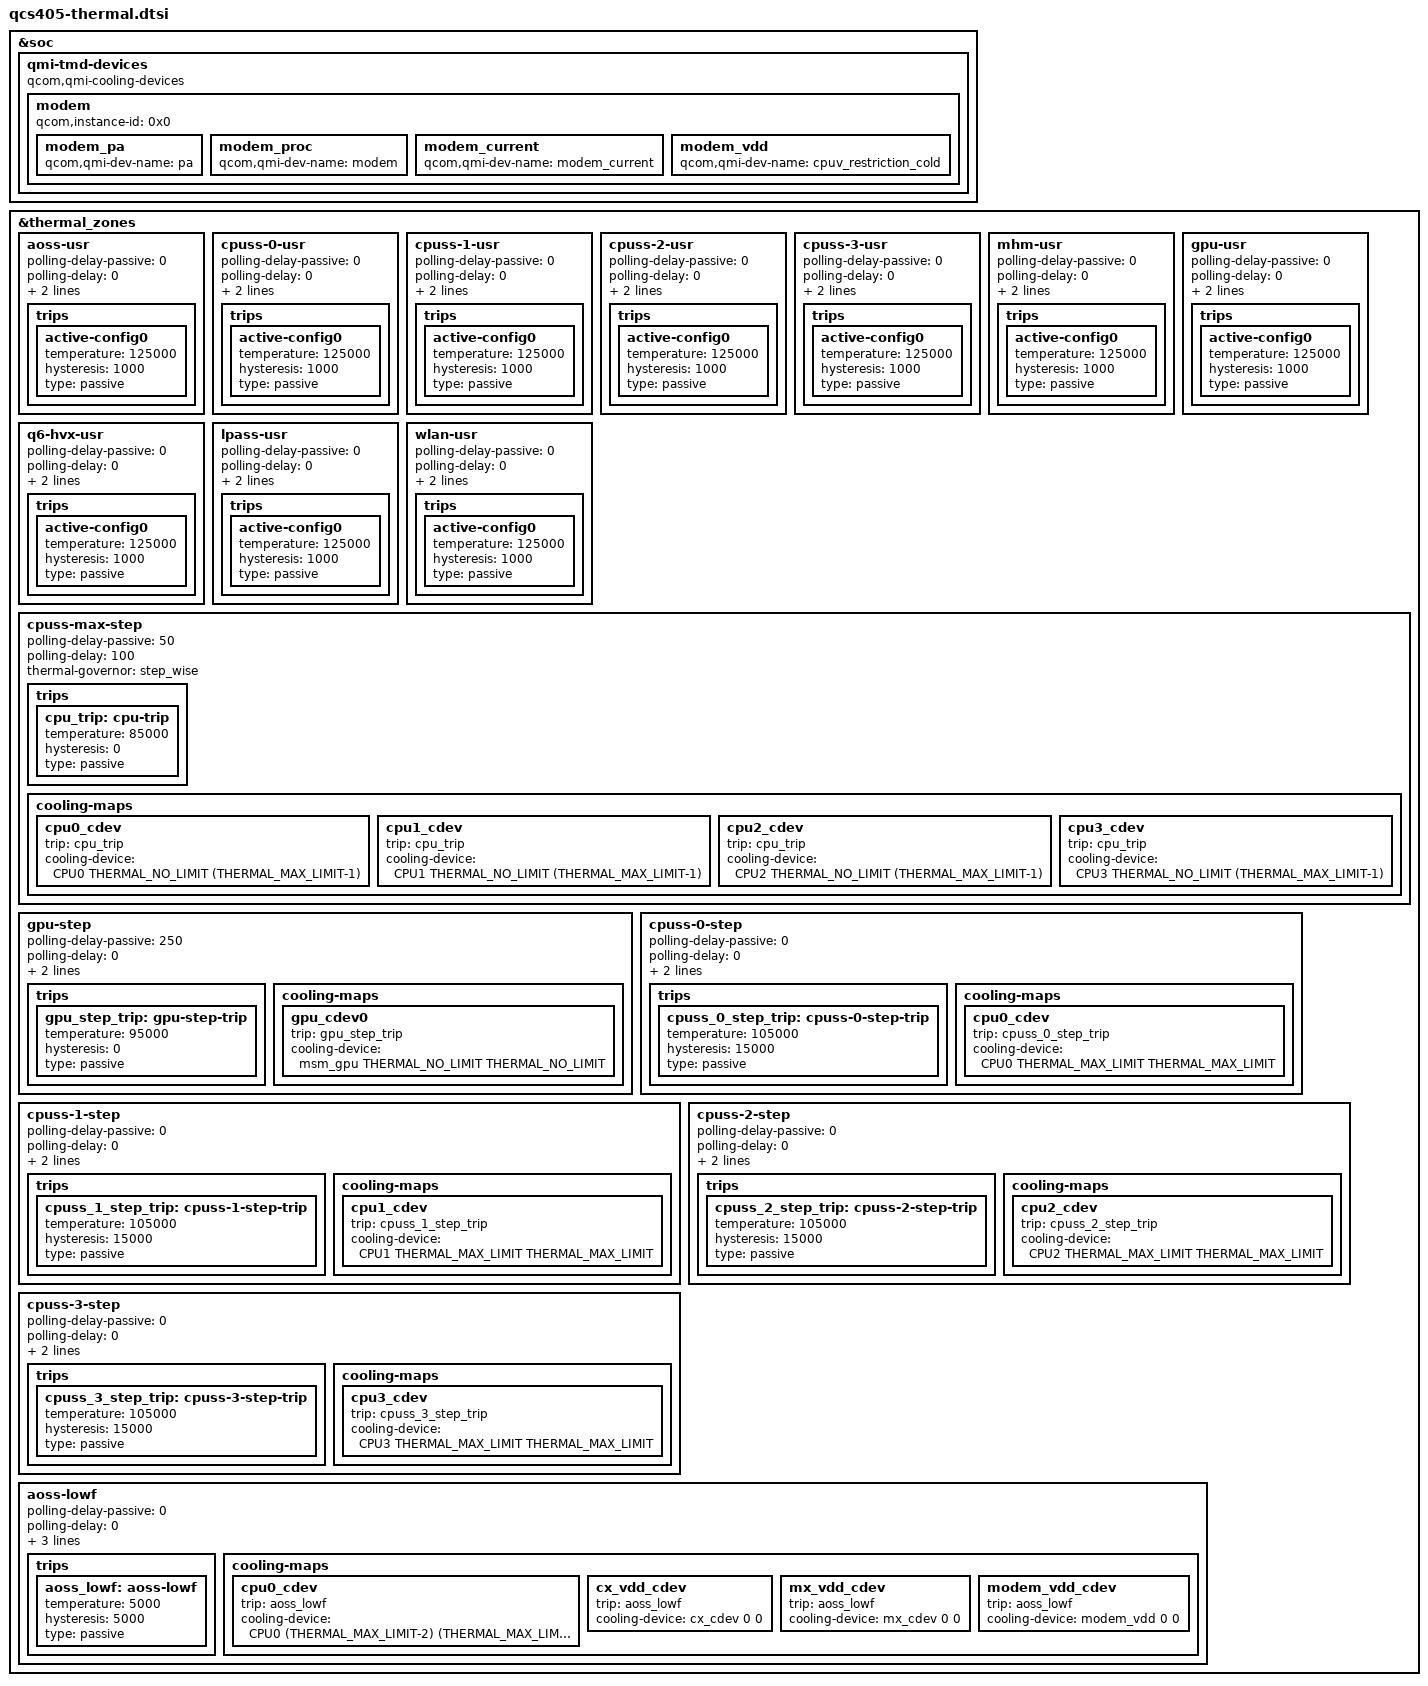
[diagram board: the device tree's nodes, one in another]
/* Copyright (c) 2018, The Linux Foundation. All rights reserved.
 *
 * This program is free software; you can redistribute it and/or modify
 * it under the terms of the GNU General Public License version 2 and
 * only version 2 as published by the Free Software Foundation.
 *
 * This program is distributed in the hope that it will be useful,
 * but WITHOUT ANY WARRANTY; without even the implied warranty of
 * MERCHANTABILITY or FITNESS FOR A PARTICULAR PURPOSE.  See the
 * GNU General Public License for more details.
 */

#include <dt-bindings/thermal/thermal.h>

&soc {
	qmi-tmd-devices {
		compatible = "qcom,qmi-cooling-devices";

		modem {
			qcom,instance-id = <0x0>;

			modem_pa: modem_pa {
				qcom,qmi-dev-name = "pa";
				#cooling-cells = <2>;
			};

			modem_proc: modem_proc {
				qcom,qmi-dev-name = "modem";
				#cooling-cells = <2>;
			};

			modem_current: modem_current {
				qcom,qmi-dev-name = "modem_current";
				#cooling-cells = <2>;
			};

			modem_vdd: modem_vdd {
				qcom,qmi-dev-name = "cpuv_restriction_cold";
				#cooling-cells = <2>;
			};
		};
	};
};

&thermal_zones {
	aoss-usr {
		polling-delay-passive = <0>;
		polling-delay = <0>;
		thermal-governor = "user_space";
		thermal-sensors = <&tsens0 0>;
		trips {
			active-config0 {
				temperature = <125000>;
				hysteresis = <1000>;
				type = "passive";
			};
		};
	};

	cpuss-0-usr {
		polling-delay-passive = <0>;
		polling-delay = <0>;
		thermal-governor = "user_space";
		thermal-sensors = <&tsens0 1>;
		trips {
			active-config0 {
				temperature = <125000>;
				hysteresis = <1000>;
				type = "passive";
			};
		};
	};

	cpuss-1-usr {
		polling-delay-passive = <0>;
		polling-delay = <0>;
		thermal-governor = "user_space";
		thermal-sensors = <&tsens0 2>;
		trips {
			active-config0 {
				temperature = <125000>;
				hysteresis = <1000>;
				type = "passive";
			};
		};
	};

	cpuss-2-usr {
		polling-delay-passive = <0>;
		polling-delay = <0>;
		thermal-governor = "user_space";
		thermal-sensors = <&tsens0 3>;
		trips {
			active-config0 {
				temperature = <125000>;
				hysteresis = <1000>;
				type = "passive";
			};
		};
	};

	cpuss-3-usr {
		polling-delay-passive = <0>;
		polling-delay = <0>;
		thermal-sensors = <&tsens0 4>;
		thermal-governor = "user_space";
		trips {
			active-config0 {
				temperature = <125000>;
				hysteresis = <1000>;
				type = "passive";
			};
		};
	};

	mhm-usr {
		polling-delay-passive = <0>;
		polling-delay = <0>;
		thermal-sensors = <&tsens0 5>;
		thermal-governor = "user_space";
		trips {
			active-config0 {
				temperature = <125000>;
				hysteresis = <1000>;
				type = "passive";
			};
		};
	};

	gpu-usr {
		polling-delay-passive = <0>;
		polling-delay = <0>;
		thermal-sensors = <&tsens0 6>;
		thermal-governor = "user_space";
		trips {
			active-config0 {
				temperature = <125000>;
				hysteresis = <1000>;
				type = "passive";
			};
		};
	};

	q6-hvx-usr {
		polling-delay-passive = <0>;
		polling-delay = <0>;
		thermal-sensors = <&tsens0 7>;
		thermal-governor = "user_space";
		trips {
			active-config0 {
				temperature = <125000>;
				hysteresis = <1000>;
				type = "passive";
			};
		};
	};

	lpass-usr {
		polling-delay-passive = <0>;
		polling-delay = <0>;
		thermal-sensors = <&tsens0 8>;
		thermal-governor = "user_space";
		trips {
			active-config0 {
				temperature = <125000>;
				hysteresis = <1000>;
				type = "passive";
			};
		};
	};

	wlan-usr {
		polling-delay-passive = <0>;
		polling-delay = <0>;
		thermal-sensors = <&tsens0 9>;
		thermal-governor = "user_space";
		trips {
			active-config0 {
				temperature = <125000>;
				hysteresis = <1000>;
				type = "passive";
			};
		};
	};

	cpuss-max-step {
		polling-delay-passive = <50>;
		polling-delay = <100>;
		thermal-governor = "step_wise";
		trips {
			cpu_trip:cpu-trip {
				temperature = <85000>;
				hysteresis = <0>;
				type = "passive";
			};
		};
		cooling-maps {
			cpu0_cdev {
				trip = <&cpu_trip>;
				cooling-device =
					<&CPU0 THERMAL_NO_LIMIT
						(THERMAL_MAX_LIMIT-1)>;
			};
			cpu1_cdev {
				trip = <&cpu_trip>;
				cooling-device =
					<&CPU1 THERMAL_NO_LIMIT
						(THERMAL_MAX_LIMIT-1)>;
			};
			cpu2_cdev {
				trip = <&cpu_trip>;
				cooling-device =
					<&CPU2 THERMAL_NO_LIMIT
						(THERMAL_MAX_LIMIT-1)>;
			};
			cpu3_cdev {
				trip = <&cpu_trip>;
				cooling-device =
					<&CPU3 THERMAL_NO_LIMIT
						(THERMAL_MAX_LIMIT-1)>;
			};
		};
	};

	gpu-step {
		polling-delay-passive = <250>;
		polling-delay = <0>;
		thermal-sensors = <&tsens0 6>;
		thermal-governor = "step_wise";
		trips {
			gpu_step_trip: gpu-step-trip {
				temperature = <95000>;
				hysteresis = <0>;
				type = "passive";
			};
		};
		cooling-maps {
			gpu_cdev0 {
				trip = <&gpu_step_trip>;
				cooling-device =
					<&msm_gpu THERMAL_NO_LIMIT
						THERMAL_NO_LIMIT>;
			};
		};
	};

	cpuss-0-step {
		polling-delay-passive = <0>;
		polling-delay = <0>;
		thermal-sensors = <&tsens0 1>;
		thermal-governor = "step_wise";
		trips {
			cpuss_0_step_trip: cpuss-0-step-trip {
				temperature = <105000>;
				hysteresis = <15000>;
				type = "passive";
			};
		};
		cooling-maps {
			cpu0_cdev {
				trip = <&cpuss_0_step_trip>;
				cooling-device =
					<&CPU0 THERMAL_MAX_LIMIT
						THERMAL_MAX_LIMIT>;
			};
		};
	};

	cpuss-1-step {
		polling-delay-passive = <0>;
		polling-delay = <0>;
		thermal-sensors = <&tsens0 2>;
		thermal-governor = "step_wise";
		trips {
			cpuss_1_step_trip: cpuss-1-step-trip {
				temperature = <105000>;
				hysteresis = <15000>;
				type = "passive";
			};
		};
		cooling-maps {
			cpu1_cdev {
				trip = <&cpuss_1_step_trip>;
				cooling-device =
					<&CPU1 THERMAL_MAX_LIMIT
						THERMAL_MAX_LIMIT>;
			};
		};
	};

	cpuss-2-step {
		polling-delay-passive = <0>;
		polling-delay = <0>;
		thermal-sensors = <&tsens0 3>;
		thermal-governor = "step_wise";
		trips {
			cpuss_2_step_trip: cpuss-2-step-trip {
				temperature = <105000>;
				hysteresis = <15000>;
				type = "passive";
			};
		};
		cooling-maps {
			cpu2_cdev {
				trip = <&cpuss_2_step_trip>;
				cooling-device =
					<&CPU2 THERMAL_MAX_LIMIT
						THERMAL_MAX_LIMIT>;
			};
		};
	};

	cpuss-3-step {
		polling-delay-passive = <0>;
		polling-delay = <0>;
		thermal-sensors = <&tsens0 4>;
		thermal-governor = "step_wise";
		trips {
			cpuss_3_step_trip: cpuss-3-step-trip {
				temperature = <105000>;
				hysteresis = <15000>;
				type = "passive";
			};
		};
		cooling-maps {
			cpu3_cdev {
				trip = <&cpuss_3_step_trip>;
				cooling-device =
					<&CPU3 THERMAL_MAX_LIMIT
						THERMAL_MAX_LIMIT>;
			};
		};
	};

	aoss-lowf {
		polling-delay-passive = <0>;
		polling-delay = <0>;
		thermal-governor = "low_limits_floor";
		thermal-sensors = <&tsens0 0>;
		tracks-low;
		trips {
			aoss_lowf: aoss-lowf {
				temperature = <5000>;
				hysteresis = <5000>;
				type = "passive";
			};
		};
		cooling-maps {
			cpu0_cdev {
				trip = <&aoss_lowf>;
				cooling-device = <&CPU0 (THERMAL_MAX_LIMIT-2)
							(THERMAL_MAX_LIMIT-2)>;
			};
			cx_vdd_cdev {
				trip = <&aoss_lowf>;
				cooling-device = <&cx_cdev 0 0>;
			};
			mx_vdd_cdev {
				trip = <&aoss_lowf>;
				cooling-device = <&mx_cdev 0 0>;
			};
			modem_vdd_cdev {
				trip = <&aoss_lowf>;
				cooling-device = <&modem_vdd 0 0>;
			};
		};
	};
};
